VERSION ""

NS_ :

BS_:

BU_: Mirror BCM

BO_ 7 Sleep_ack_msg: 1 Vector__XXX
 SG_ Sleep_ack_signal : 0|8@1- (1,0) [0|0] "" Vector__XXX

BO_ 6 Sleep_msg: 1 BCM
 SG_ Sleep_signal : 0|1@1+ (1,0) [0|0] "" Vector__XXX

BO_ 5 Mirror_Status_mesg: 2 Mirror
 SG_ L_mirror_position : 8|8@1+ (1,0) [0|90] "" Vector__XXX
 SG_ R_mirror_position : 0|8@1+ (1,0) [0|90] "" Vector__XXX

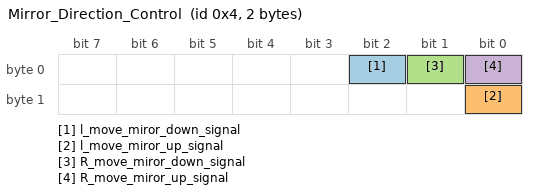
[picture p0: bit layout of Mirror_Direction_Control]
BO_ 4 Mirror_Direction_Control: 2 Vector__XXX
 SG_ l_move_miror_down_signal : 2|1@1+ (1,0) [0|1] "" Vector__XXX
 SG_ l_move_miror_up_signal : 8|1@1+ (1,0) [0|255] "" Vector__XXX
 SG_ R_move_miror_down_signal : 1|1@1+ (1,0) [0|0] "" Vector__XXX
 SG_ R_move_miror_up_signal : 0|1@1+ (1,0) [0|0] "" Vector__XXX

BO_ 3 Close_msg: 1 BCM
 SG_ Close_Signal : 0|1@1+ (1,0) [0|1] "" Vector__XXX

BO_ 2 Open_msg: 1 BCM
 SG_ Open_Signal : 0|1@1+ (1,0) [0|1] "" Vector__XXX

BO_ 1 Wakeup_Ack_msg: 1 Mirror
 SG_ Wakeup_Signal : 0|1@1+ (1,0) [0|1] "" Vector__XXX

BO_ 0 NM_msg: 1 BCM
 SG_ wake_up_signal : 7|1@0+ (1,0) [0|1] "" Vector__XXX

BA_DEF_ BO_  "CANFD_BRS" ENUM  "0","1";
BA_DEF_  "DBName" STRING ;
BA_DEF_  "BusType" STRING ;
BA_DEF_ BO_  "VFrameFormat" ENUM  "StandardCAN","ExtendedCAN","reserved","reserved","reserved","reserved","reserved","reserved","reserved","reserved","reserved","reserved","reserved","reserved","StandardCAN_FD","ExtendedCAN_FD";
BA_DEF_DEF_  "CANFD_BRS" "1";
BA_DEF_DEF_  "DBName" "";
BA_DEF_DEF_  "BusType" "";
BA_DEF_DEF_  "VFrameFormat" "StandardCAN";
BA_ "BusType" "CAN FD";
BA_ "DBName" "MirrorControl";
